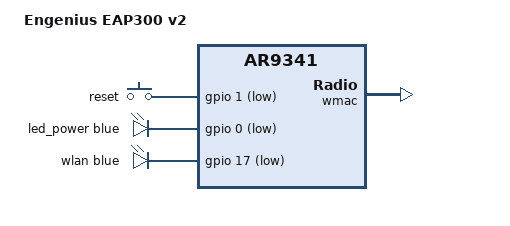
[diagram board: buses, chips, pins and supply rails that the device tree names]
// SPDX-License-Identifier: GPL-2.0-or-later OR MIT

#include "ar9341.dtsi"
#include "ar934x_senao_loader.dtsi"

#include <dt-bindings/gpio/gpio.h>
#include <dt-bindings/input/input.h>
#include <dt-bindings/leds/common.h>

/ {
	model = "Engenius EAP300 v2";
	compatible = "engenius,eap300-v2", "qca,ar9341";

	aliases {
		led-boot = &led_power;
		led-failsafe = &led_power;
		led-running = &led_power;
		led-upgrade = &led_power;
	};

	keys {
		compatible = "gpio-keys";

		reset {
			label = "reset";
			gpios = <&gpio 1 GPIO_ACTIVE_LOW>;
			debounce-interval = <60>;
			linux,code = <KEY_RESTART>;
		};
	};

	leds {
		compatible = "gpio-leds";

		led_power: power {
			function = LED_FUNCTION_POWER;
			color = <LED_COLOR_ID_BLUE>;
			gpios = <&gpio 0 GPIO_ACTIVE_LOW>;
			default-state = "on";
		};

		wlan {
			function = LED_FUNCTION_WLAN;
			color = <LED_COLOR_ID_BLUE>;
			gpios = <&gpio 17 GPIO_ACTIVE_LOW>;
			linux,default-trigger = "phy0tpt";
		};
	};
};

&eth1 {
	nvmem-cells = <&macaddr_art_0>;
	nvmem-cell-names = "mac-address";
};

&wmac {
	status = "okay";

	nvmem-cells = <&cal_art_1000>;
	nvmem-cell-names = "calibration";
};

&art {
	nvmem-layout {
		compatible = "fixed-layout";
		#address-cells = <1>;
		#size-cells = <1>;

		macaddr_art_0: macaddr@0 {
			reg = <0x0 0x6>;
		};

		cal_art_1000: calibration@1000 {
			reg = <0x1000 0x440>;
		};
	};
};
